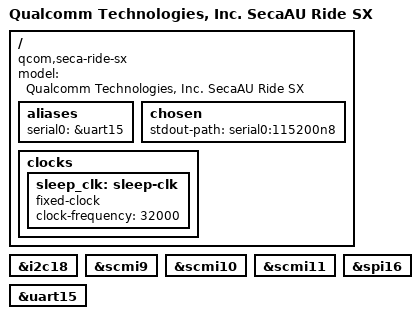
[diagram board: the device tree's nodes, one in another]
// SPDX-License-Identifier: BSD-3-Clause
/*
 * Copyright (c) Qualcomm Technologies, Inc. and/or its subsidiaries.
 */

/dts-v1/;

#include "seca-gearvm.dtsi"

/ {
	model = "Qualcomm Technologies, Inc. SecaAU Ride SX";
	compatible = "qcom,seca-ride-sx", "qcom,seca";

	aliases {
		serial0 = &uart15;
	};

	chosen {
		stdout-path = "serial0:115200n8";
	};

	clocks {
		sleep_clk: sleep-clk {
			compatible = "fixed-clock";
			clock-frequency = <32000>;
			#clock-cells = <0>;
		};
	};
};

&i2c18 {
	status = "okay";
};

&scmi9 {
	status = "okay";
};

&scmi10 {
	status = "okay";
};

&scmi11 {
	status = "okay";
};

&spi16 {
	status = "okay";
};

&uart15 {
	status = "okay";
};
